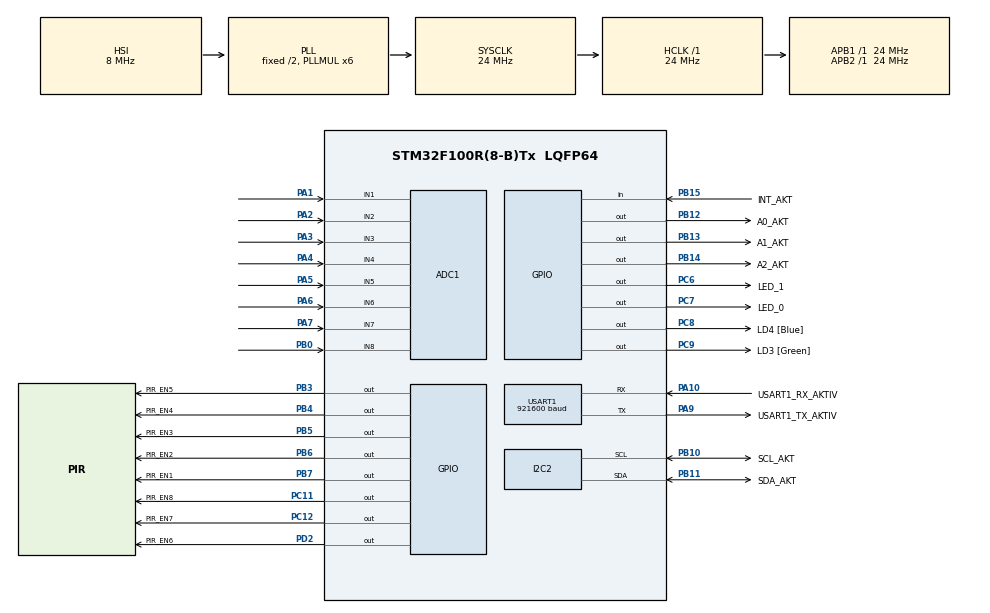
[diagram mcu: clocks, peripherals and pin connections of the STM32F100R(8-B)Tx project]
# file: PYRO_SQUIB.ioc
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ADC1.Channel-0\#ChannelRegularConversion=ADC_CHANNEL_1
ADC1.Channel-1\#ChannelRegularConversion=ADC_CHANNEL_2
ADC1.Channel-2\#ChannelRegularConversion=ADC_CHANNEL_3
ADC1.Channel-3\#ChannelRegularConversion=ADC_CHANNEL_4
ADC1.Channel-4\#ChannelRegularConversion=ADC_CHANNEL_5
ADC1.Channel-5\#ChannelRegularConversion=ADC_CHANNEL_6
ADC1.Channel-6\#ChannelRegularConversion=ADC_CHANNEL_7
ADC1.Channel-7\#ChannelRegularConversion=ADC_CHANNEL_8
ADC1.ContinuousConvMode=ENABLE
ADC1.DataAlign=ADC_DATAALIGN_RIGHT
ADC1.DiscontinuousConvMode=DISABLE
ADC1.EnableAnalogWatchDog=false
ADC1.EnableRegularConversion=ENABLE
ADC1.ExternalTrigConv=ADC_SOFTWARE_START
ADC1.InjNumberOfConversion=0
ADC1.NbrOfConversion=8
ADC1.NbrOfConversionFlag=1
ADC1.Rank-0\#ChannelRegularConversion=1
ADC1.Rank-1\#ChannelRegularConversion=2
ADC1.Rank-2\#ChannelRegularConversion=3
ADC1.Rank-3\#ChannelRegularConversion=4
ADC1.Rank-4\#ChannelRegularConversion=5
ADC1.Rank-5\#ChannelRegularConversion=6
ADC1.Rank-6\#ChannelRegularConversion=7
ADC1.Rank-7\#ChannelRegularConversion=8
ADC1.SamplingTime-0\#ChannelRegularConversion=ADC_SAMPLETIME_55CYCLES_5
ADC1.SamplingTime-1\#ChannelRegularConversion=ADC_SAMPLETIME_55CYCLES_5
ADC1.SamplingTime-2\#ChannelRegularConversion=ADC_SAMPLETIME_55CYCLES_5
ADC1.SamplingTime-3\#ChannelRegularConversion=ADC_SAMPLETIME_55CYCLES_5
ADC1.SamplingTime-4\#ChannelRegularConversion=ADC_SAMPLETIME_55CYCLES_5
ADC1.SamplingTime-5\#ChannelRegularConversion=ADC_SAMPLETIME_55CYCLES_5
ADC1.SamplingTime-6\#ChannelRegularConversion=ADC_SAMPLETIME_55CYCLES_5
ADC1.SamplingTime-7\#ChannelRegularConversion=ADC_SAMPLETIME_55CYCLES_5
ADC1.ScanConvMode=ADC_SCAN_ENABLE
ADC1.master=1
Dma.ADC1.2.Direction=DMA_PERIPH_TO_MEMORY
Dma.ADC1.2.Instance=DMA1_Channel1
Dma.ADC1.2.MemDataAlignment=DMA_MDATAALIGN_HALFWORD
Dma.ADC1.2.MemInc=DMA_MINC_ENABLE
Dma.ADC1.2.Mode=DMA_CIRCULAR
Dma.ADC1.2.PeriphDataAlignment=DMA_PDATAALIGN_HALFWORD
Dma.ADC1.2.PeriphInc=DMA_PINC_DISABLE
Dma.ADC1.2.Priority=DMA_PRIORITY_MEDIUM
Dma.Request0=USART1_RX
Dma.Request1=USART1_TX
Dma.Request2=ADC1
Dma.USART1_RX.0.Direction=DMA_PERIPH_TO_MEMORY
Dma.USART1_RX.0.Instance=DMA1_Channel5
Dma.USART1_RX.0.MemDataAlignment=DMA_MDATAALIGN_BYTE
Dma.USART1_RX.0.MemInc=DMA_MINC_ENABLE
Dma.USART1_RX.0.Mode=DMA_NORMAL
Dma.USART1_RX.0.PeriphDataAlignment=DMA_PDATAALIGN_BYTE
Dma.USART1_RX.0.PeriphInc=DMA_PINC_DISABLE
Dma.USART1_RX.0.Priority=DMA_PRIORITY_HIGH
Dma.USART1_TX.1.Direction=DMA_MEMORY_TO_PERIPH
Dma.USART1_TX.1.Instance=DMA1_Channel4
Dma.USART1_TX.1.MemDataAlignment=DMA_MDATAALIGN_BYTE
Dma.USART1_TX.1.MemInc=DMA_MINC_ENABLE
Dma.USART1_TX.1.Mode=DMA_NORMAL
Dma.USART1_TX.1.PeriphDataAlignment=DMA_PDATAALIGN_BYTE
Dma.USART1_TX.1.PeriphInc=DMA_PINC_DISABLE
Dma.USART1_TX.1.Priority=DMA_PRIORITY_HIGH
FREERTOS.HEAP_NUMBER=1
FREERTOS.INCLUDE_uxTaskPriorityGet=0
FREERTOS.INCLUDE_vTaskDelete=0
FREERTOS.Tasks01=defaultTask,-3,256,StartDefaultTask,Default,NULL,Dynamic,NULL,NULL
FREERTOS.configTOTAL_HEAP_SIZE=4096
Mcu.Family=STM32F1
Mcu.Name=STM32F100R(8-B)Tx
Mcu.Package=LQFP64
NVIC.DMA1_Channel1_IRQn=true\:7\:0\:true\:false\:true\:true
NVIC.DMA1_Channel4_IRQn=true\:5\:0\:false\:false\:true\:true
NVIC.DMA1_Channel5_IRQn=true\:5\:0\:false\:false\:true\:true
NVIC.PriorityGroup=NVIC_PRIORITYGROUP_4
NVIC.TIM2_IRQn=true\:5\:0\:false\:false\:true\:true
NVIC.TIM4_IRQn=true\:5\:0\:false\:false\:true\:true
NVIC.USART1_IRQn=true\:6\:0\:true\:false\:true\:true
PA1.Signal=ADCx_IN1
PA10.GPIO_Label=USART1_RX_AKTIV 
PA10.Mode=Asynchronous
PA10.Signal=USART1_RX
PA13.GPIO_Label=TMS_SWDIO
PA13.Mode=Serial_Wire
PA13.Signal=SYS_JTMS-SWDIO
PA14.GPIO_Label=TCK_SWCLK
PA14.Mode=Serial_Wire
PA14.Signal=SYS_JTCK-SWCLK
PA2.Signal=ADCx_IN2
PA3.Signal=ADCx_IN3
PA4.Signal=ADCx_IN4
PA5.Signal=ADCx_IN5
PA6.Signal=ADCx_IN6
PA7.Signal=ADCx_IN7
PA9.GPIO_Label=USART1_TX_AKTIV 
PA9.Mode=Asynchronous
PA9.Signal=USART1_TX
PB0.Signal=ADCx_IN8
PB10.GPIO_Label=SCL_AKT
PB10.Mode=I2C
PB10.Signal=I2C2_SCL
PB11.GPIO_Label=SDA_AKT
PB11.Mode=I2C
PB11.Signal=I2C2_SDA
PB12.GPIO_Label=A0_AKT
PB12.Signal=GPIO_Output
PB13.GPIO_Label=A1_AKT
PB13.Signal=GPIO_Output
PB14.GPIO_Label=A2_AKT
PB14.Signal=GPIO_Output
PB15.GPIO_Label=INT_AKT
PB15.Signal=GPIO_Input
PB3.GPIO_Label=PIR_EN5
PB3.Signal=GPIO_Output
PB4.GPIO_Label=PIR_EN4
PB4.Signal=GPIO_Output
PB5.GPIO_Label=PIR_EN3
PB5.Signal=GPIO_Output
PB6.GPIO_Label=PIR_EN2
PB6.Signal=GPIO_Output
PB7.GPIO_Label=PIR_EN1
PB7.Signal=GPIO_Output
PC11.GPIO_Label=PIR_EN8
PC11.Signal=GPIO_Output
PC12.GPIO_Label=PIR_EN7
PC12.Signal=GPIO_Output
PC14-OSC32_IN.Signal=RCC_OSC32_IN
PC15-OSC32_OUT.Signal=RCC_OSC32_OUT
PC6.GPIO_Label=LED_1
PC6.Signal=GPIO_Output
PC7.GPIO_Label=LED_0
PC7.Signal=GPIO_Output
PC8.GPIO_Label=LD4 [Blue]
PC8.Signal=GPIO_Output
PC9.GPIO_Label=LD3 [Green]
PC9.Signal=GPIO_Output
PD2.GPIO_Label=PIR_EN6
PD2.Signal=GPIO_Output
ProjectManager.HeapSize=0x200
ProjectManager.StackSize=0x400
ProjectManager.TargetToolchain=MDK-ARM V5
RCC.AHBFreq_Value=24000000
RCC.APB1Freq_Value=24000000
RCC.APB1TimFreq_Value=24000000
RCC.APB2Freq_Value=24000000
RCC.APB2TimFreq_Value=24000000
RCC.HCLKFreq_Value=24000000
RCC.PLLMUL=RCC_PLL_MUL6
RCC.SYSCLKFreq_VALUE=24000000
RCC.SYSCLKSource=RCC_SYSCLKSOURCE_PLLCLK
SH.ADCx_IN1.0=ADC1_IN1,IN1
SH.ADCx_IN2.0=ADC1_IN2,IN2
SH.ADCx_IN3.0=ADC1_IN3,IN3
SH.ADCx_IN4.0=ADC1_IN4,IN4
SH.ADCx_IN5.0=ADC1_IN5,IN5
SH.ADCx_IN6.0=ADC1_IN6,IN6
SH.ADCx_IN7.0=ADC1_IN7,IN7
SH.ADCx_IN8.0=ADC1_IN8,IN8
TIM2.Period=10
TIM2.Prescaler=24000
TIM4.Period=1200
USART1.BaudRate=921600
USART1.VirtualMode=VM_ASYNC
VP_FREERTOS_VS_ENABLE.Mode=Enabled
VP_TIM2_VS_ClockSourceINT.Mode=Internal
VP_TIM2_VS_OPM.Mode=OPM_bit
VP_TIM4_VS_ClockSourceINT.Mode=Internal
board=PYRO_SQUIB

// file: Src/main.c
/**
  ******************************************************************************
  * File Name          : main.c
  * Description        : Main program body
  ******************************************************************************
  *
  * Copyright (c) 2017 STMicroelectronics International N.V.
  * All rights reserved.
  *
  * Redistribution and use in source and binary forms, with or without
  * modification, are permitted, provided that the following conditions are met:
  *
  * 1. Redistribution of source code must retain the above copyright notice,
  *    this list of conditions and the following disclaimer.
  * 2. Redistributions in binary form must reproduce the above copyright notice,
  *    this list of conditions and the following disclaimer in the documentation
  *    and/or other materials provided with the distribution.
  * 3. Neither the name of STMicroelectronics nor the names of other
  *    contributors to this software may be used to endorse or promote products
  *    derived from this software without specific written permission.
  * 4. This software, including modifications and/or derivative works of this
  *    software, must execute solely and exclusively on microcontroller or
  *    microprocessor devices manufactured by or for STMicroelectronics.
  * 5. Redistribution and use of this software other than as permitted under
  *    this license is void and will automatically terminate your rights under
  *    this license.
  *
  * THIS SOFTWARE IS PROVIDED BY STMICROELECTRONICS AND CONTRIBUTORS "AS IS"
  * AND ANY EXPRESS, IMPLIED OR STATUTORY WARRANTIES, INCLUDING, BUT NOT
  * LIMITED TO, THE IMPLIED WARRANTIES OF MERCHANTABILITY, FITNESS FOR A
  * PARTICULAR PURPOSE AND NON-INFRINGEMENT OF THIRD PARTY INTELLECTUAL PROPERTY
  * RIGHTS ARE DISCLAIMED TO THE FULLEST EXTENT PERMITTED BY LAW. IN NO EVENT
  * SHALL STMICROELECTRONICS OR CONTRIBUTORS BE LIABLE FOR ANY DIRECT, INDIRECT,
  * INCIDENTAL, SPECIAL, EXEMPLARY, OR CONSEQUENTIAL DAMAGES (INCLUDING, BUT NOT
  * LIMITED TO, PROCUREMENT OF SUBSTITUTE GOODS OR SERVICES; LOSS OF USE, DATA,
  * OR PROFITS; OR BUSINESS INTERRUPTION) HOWEVER CAUSED AND ON ANY THEORY OF
  * LIABILITY, WHETHER IN CONTRACT, STRICT LIABILITY, OR TORT (INCLUDING
  * NEGLIGENCE OR OTHERWISE) ARISING IN ANY WAY OUT OF THE USE OF THIS SOFTWARE,
  * EVEN IF ADVISED OF THE POSSIBILITY OF SUCH DAMAGE.
  *
  ******************************************************************************
  */
#include "main.h"
#include "stm32f1xx_hal.h"
#include "cmsis_os.h"

/* USER CODE BEGIN Includes */
#include "mbinit.h"
#include "adc.h"
#include "dig_pot.h"
#include "pyro_squib.h"
#include "cfg_info.h"
/* USER CODE END Includes */

ADC_HandleTypeDef hadc1;
DMA_HandleTypeDef hdma_adc1;

I2C_HandleTypeDef hi2c2;

TIM_HandleTypeDef htim2;
TIM_HandleTypeDef htim4;

UART_HandleTypeDef huart1;
DMA_HandleTypeDef hdma_usart1_rx;
DMA_HandleTypeDef hdma_usart1_tx;

osThreadId defaultTaskHandle;

/* USER CODE BEGIN PV */
/* Private variables ---------------------------------------------------------*/

/* USER CODE END PV */

void SystemClock_Config(void);
void Error_Handler(void);
static void MX_GPIO_Init(void);
static void MX_DMA_Init(void);
static void MX_ADC1_Init(void);
static void MX_USART1_UART_Init(void);
static void MX_TIM4_Init(void);
static void MX_I2C2_Init(void);
static void MX_TIM2_Init(void);
void StartDefaultTask(void const * argument);

int main(void)
{

  /* MCU Configuration----------------------------------------------------------*/

  /* Reset of all peripherals, Initializes the Flash interface and the Systick. */
	HAL_Init();

  /* Configure the system clock */
//  SystemClock_Config();

  /* Initialize all configured peripherals */
	MX_GPIO_Init();
	MX_DMA_Init();
	MX_ADC1_Init();
	MX_USART1_UART_Init();
	MX_TIM4_Init();
	MX_I2C2_Init();
	MX_TIM2_Init();

  /* USER CODE BEGIN 2 */

	SystemClock_Config();
	ConfigInfoRead ();
	HAL_NVIC_DisableIRQ(DMA1_Channel1_IRQn);

	DigPot_Init();
	ADC_Init();
	PyroSquib_Init();
	Modbus_Init();

  /* USER CODE END 2 */

  /* Create the thread(s) */
  /* definition and creation of defaultTask */
//  osThreadDef(defaultTask, StartDefaultTask, osPriorityIdle, 5, 256);
//  defaultTaskHandle = osThreadCreate(osThread(defaultTask), NULL);

  /* Start scheduler */
  osKernelStart();

  /* We should never get here as control is now taken by the scheduler */

  /* Infinite loop */
  while (1)
  {

  }

}

/** System Clock Configuration
*/
void SystemClock_Config(void)
{

  RCC_OscInitTypeDef RCC_OscInitStruct;
  RCC_ClkInitTypeDef RCC_ClkInitStruct;
  RCC_PeriphCLKInitTypeDef PeriphClkInit;

    /**Initializes the CPU, AHB and APB busses clocks
    */
  RCC_OscInitStruct.OscillatorType = RCC_OSCILLATORTYPE_HSI;
  RCC_OscInitStruct.HSIState = RCC_HSI_ON;
  RCC_OscInitStruct.HSICalibrationValue = 16;
  RCC_OscInitStruct.PLL.PLLState = RCC_PLL_ON;
  RCC_OscInitStruct.PLL.PLLSource = RCC_PLLSOURCE_HSI_DIV2;
  RCC_OscInitStruct.PLL.PLLMUL = RCC_PLL_MUL6;
  if (HAL_RCC_OscConfig(&RCC_OscInitStruct) != HAL_OK)
  {
    Error_Handler();
  }

    /**Initializes the CPU, AHB and APB busses clocks
    */
  RCC_ClkInitStruct.ClockType = RCC_CLOCKTYPE_HCLK|RCC_CLOCKTYPE_SYSCLK
                              |RCC_CLOCKTYPE_PCLK1|RCC_CLOCKTYPE_PCLK2;
  RCC_ClkInitStruct.SYSCLKSource = RCC_SYSCLKSOURCE_PLLCLK;
  RCC_ClkInitStruct.AHBCLKDivider = RCC_SYSCLK_DIV1;
  RCC_ClkInitStruct.APB1CLKDivider = RCC_HCLK_DIV1;
  RCC_ClkInitStruct.APB2CLKDivider = RCC_HCLK_DIV1;

  if (HAL_RCC_ClockConfig(&RCC_ClkInitStruct, FLASH_LATENCY_0) != HAL_OK)
  {
    Error_Handler();
  }

  PeriphClkInit.PeriphClockSelection = RCC_PERIPHCLK_ADC;
  PeriphClkInit.AdcClockSelection = RCC_ADCPCLK2_DIV2;
  if (HAL_RCCEx_PeriphCLKConfig(&PeriphClkInit) != HAL_OK)
  {
    Error_Handler();
  }

    /**Configure the Systick interrupt time
    */
  HAL_SYSTICK_Config(HAL_RCC_GetHCLKFreq()/1000);

    /**Configure the Systick
    */
  HAL_SYSTICK_CLKSourceConfig(SYSTICK_CLKSOURCE_HCLK);

  /* SysTick_IRQn interrupt configuration */
  HAL_NVIC_SetPriority(SysTick_IRQn, 15, 0);
}

/* ADC1 init function */
static void MX_ADC1_Init(void)
{

  ADC_ChannelConfTypeDef sConfig;

    /**Common config
    */
  hadc1.Instance = ADC1;
  hadc1.Init.ScanConvMode = ADC_SCAN_ENABLE;
  hadc1.Init.ContinuousConvMode = ENABLE;
  hadc1.Init.DiscontinuousConvMode = DISABLE;
  hadc1.Init.ExternalTrigConv = ADC_SOFTWARE_START;
  hadc1.Init.DataAlign = ADC_DATAALIGN_RIGHT;
  hadc1.Init.NbrOfConversion = 8;
  if (HAL_ADC_Init(&hadc1) != HAL_OK)
  {
    Error_Handler();
  }

    /**Configure Regular Channel
    */
  sConfig.Channel = ADC_CHANNEL_1;
  sConfig.Rank = 1;
  sConfig.SamplingTime = ADC_SAMPLETIME_13CYCLES_5;
  if (HAL_ADC_ConfigChannel(&hadc1, &sConfig) != HAL_OK)
  {
    Error_Handler();
  }

    /**Configure Regular Channel
    */
  sConfig.Channel = ADC_CHANNEL_2;
  sConfig.Rank = 2;
  if (HAL_ADC_ConfigChannel(&hadc1, &sConfig) != HAL_OK)
  {
    Error_Handler();
  }

    /**Configure Regular Channel
    */
  sConfig.Channel = ADC_CHANNEL_3;
  sConfig.Rank = 3;
  if (HAL_ADC_ConfigChannel(&hadc1, &sConfig) != HAL_OK)
  {
    Error_Handler();
  }

    /**Configure Regular Channel
    */
  sConfig.Channel = ADC_CHANNEL_4;
  sConfig.Rank = 4;
  if (HAL_ADC_ConfigChannel(&hadc1, &sConfig) != HAL_OK)
  {
    Error_Handler();
  }

    /**Configure Regular Channel
    */
  sConfig.Channel = ADC_CHANNEL_5;
  sConfig.Rank = 5;
  if (HAL_ADC_ConfigChannel(&hadc1, &sConfig) != HAL_OK)
  {
    Error_Handler();
  }

    /**Configure Regular Channel
    */
  sConfig.Channel = ADC_CHANNEL_6;
  sConfig.Rank = 6;
  if (HAL_ADC_ConfigChannel(&hadc1, &sConfig) != HAL_OK)
  {
    Error_Handler();
  }

    /**Configure Regular Channel
    */
  sConfig.Channel = ADC_CHANNEL_7;
  sConfig.Rank = 7;
  if (HAL_ADC_ConfigChannel(&hadc1, &sConfig) != HAL_OK)
  {
    Error_Handler();
  }

    /**Configure Regular Channel
    */
  sConfig.Channel = ADC_CHANNEL_8;
  sConfig.Rank = 8;
  if (HAL_ADC_ConfigChannel(&hadc1, &sConfig) != HAL_OK)
  {
    Error_Handler();
  }

}

/* I2C2 init function */
static void MX_I2C2_Init(void)
{

  hi2c2.Instance = I2C2;
  hi2c2.Init.ClockSpeed = 100000;
  hi2c2.Init.DutyCycle = I2C_DUTYCYCLE_2;
  hi2c2.Init.OwnAddress1 = 0;
  hi2c2.Init.AddressingMode = I2C_ADDRESSINGMODE_7BIT;
  hi2c2.Init.DualAddressMode = I2C_DUALADDRESS_DISABLE;
  hi2c2.Init.OwnAddress2 = 0;
  hi2c2.Init.GeneralCallMode = I2C_GENERALCALL_DISABLE;
  hi2c2.Init.NoStretchMode = I2C_NOSTRETCH_DISABLE;
  if (HAL_I2C_Init(&hi2c2) != HAL_OK)
  {
    Error_Handler();
  }

}

/* TIM2 init function */
static void MX_TIM2_Init(void)
{

  TIM_ClockConfigTypeDef sClockSourceConfig;
  TIM_MasterConfigTypeDef sMasterConfig;

  htim2.Instance = TIM2;
  htim2.Init.Prescaler = 2400;
  htim2.Init.CounterMode = TIM_COUNTERMODE_UP;
  htim2.Init.Period = 10;
  htim2.Init.ClockDivision = TIM_CLOCKDIVISION_DIV1;
  if (HAL_TIM_Base_Init(&htim2) != HAL_OK)
  {
    Error_Handler();
  }

  sClockSourceConfig.ClockSource = TIM_CLOCKSOURCE_INTERNAL;
  if (HAL_TIM_ConfigClockSource(&htim2, &sClockSourceConfig) != HAL_OK)
  {
    Error_Handler();
  }

  if (HAL_TIM_OnePulse_Init(&htim2, TIM_OPMODE_SINGLE) != HAL_OK)
  {
    Error_Handler();
  }

  sMasterConfig.MasterOutputTrigger = TIM_TRGO_RESET;
  sMasterConfig.MasterSlaveMode = TIM_MASTERSLAVEMODE_DISABLE;
  if (HAL_TIMEx_MasterConfigSynchronization(&htim2, &sMasterConfig) != HAL_OK)
  {
    Error_Handler();
  }

}

/* TIM4 init function */
static void MX_TIM4_Init(void)
{

  TIM_ClockConfigTypeDef sClockSourceConfig;
  TIM_MasterConfigTypeDef sMasterConfig;

  htim4.Instance = TIM4;
  htim4.Init.Prescaler = 0;
  htim4.Init.CounterMode = TIM_COUNTERMODE_UP;
  htim4.Init.Period = 100;
  htim4.Init.ClockDivision = TIM_CLOCKDIVISION_DIV1;
  if (HAL_TIM_Base_Init(&htim4) != HAL_OK)
  {
    Error_Handler();
  }

  sClockSourceConfig.ClockSource = TIM_CLOCKSOURCE_INTERNAL;
  if (HAL_TIM_ConfigClockSource(&htim4, &sClockSourceConfig) != HAL_OK)
  {
    Error_Handler();
  }

  sMasterConfig.MasterOutputTrigger = TIM_TRGO_RESET;
  sMasterConfig.MasterSlaveMode = TIM_MASTERSLAVEMODE_DISABLE;
  if (HAL_TIMEx_MasterConfigSynchronization(&htim4, &sMasterConfig) != HAL_OK)
  {
    Error_Handler();
  }

}

/* USART1 init function */
static void MX_USART1_UART_Init(void)
{

  huart1.Instance = USART1;
  huart1.Init.BaudRate = 921600;
  huart1.Init.WordLength = UART_WORDLENGTH_8B;
  huart1.Init.StopBits = UART_STOPBITS_1;
  huart1.Init.Parity = UART_PARITY_NONE;
  huart1.Init.Mode = UART_MODE_TX_RX;
  huart1.Init.HwFlowCtl = UART_HWCONTROL_NONE;
  huart1.Init.OverSampling = UART_OVERSAMPLING_16;
  if (HAL_UART_Init(&huart1) != HAL_OK)
  {
    Error_Handler();
  }

}

static void MX_DMA_Init(void)
{
  /* DMA controller clock enable */
  __HAL_RCC_DMA1_CLK_ENABLE();

  /* DMA interrupt init */
  /* DMA1_Channel1_IRQn interrupt configuration */
  HAL_NVIC_SetPriority(DMA1_Channel1_IRQn, 7, 0);
  HAL_NVIC_EnableIRQ(DMA1_Channel1_IRQn);
  /* DMA1_Channel4_IRQn interrupt configuration */
  HAL_NVIC_SetPriority(DMA1_Channel4_IRQn, 5, 0);
  HAL_NVIC_EnableIRQ(DMA1_Channel4_IRQn);
  /* DMA1_Channel5_IRQn interrupt configuration */
  HAL_NVIC_SetPriority(DMA1_Channel5_IRQn, 5, 0);
  HAL_NVIC_EnableIRQ(DMA1_Channel5_IRQn);

}

/** Configure pins as
        * Analog
        * Input
        * Output
        * EVENT_OUT
        * EXTI
*/
static void MX_GPIO_Init(void)
{

  GPIO_InitTypeDef GPIO_InitStruct;

  /* GPIO Ports Clock Enable */
  __HAL_RCC_GPIOC_CLK_ENABLE();
  __HAL_RCC_GPIOA_CLK_ENABLE();
  __HAL_RCC_GPIOB_CLK_ENABLE();
  __HAL_RCC_GPIOD_CLK_ENABLE();

  /*Configure GPIO pin Output Level */
  HAL_GPIO_WritePin(GPIOB, A0_AKT_Pin|A1_AKT_Pin|A2_AKT_Pin|PIR_EN5_Pin
                          |PIR_EN4_Pin|PIR_EN3_Pin|PIR_EN2_Pin|PIR_EN1_Pin, GPIO_PIN_RESET);

  /*Configure GPIO pin Output Level */
  HAL_GPIO_WritePin(GPIOC, LED_1_Pin|LED_0_Pin|LD4_Pin|LD3_Pin
                          |PIR_EN8_Pin|PIR_EN7_Pin, GPIO_PIN_RESET);

  /*Configure GPIO pin Output Level */
  HAL_GPIO_WritePin(PIR_EN6_GPIO_Port, PIR_EN6_Pin, GPIO_PIN_RESET);

  /*Configure GPIO pins : A0_AKT_Pin A1_AKT_Pin A2_AKT_Pin PIR_EN5_Pin
                           PIR_EN4_Pin PIR_EN3_Pin PIR_EN2_Pin PIR_EN1_Pin */
  GPIO_InitStruct.Pin = A0_AKT_Pin|A1_AKT_Pin|A2_AKT_Pin|PIR_EN5_Pin
                          |PIR_EN4_Pin|PIR_EN3_Pin|PIR_EN2_Pin|PIR_EN1_Pin;
  GPIO_InitStruct.Mode = GPIO_MODE_OUTPUT_PP;
  GPIO_InitStruct.Speed = GPIO_SPEED_FREQ_LOW;
  HAL_GPIO_Init(GPIOB, &GPIO_InitStruct);

  /*Configure GPIO pin : INT_AKT_Pin */
  GPIO_InitStruct.Pin = INT_AKT_Pin;
  GPIO_InitStruct.Mode = GPIO_MODE_INPUT;
  GPIO_InitStruct.Pull = GPIO_NOPULL;
  HAL_GPIO_Init(INT_AKT_GPIO_Port, &GPIO_InitStruct);

  /*Configure GPIO pins : LED_1_Pin LED_0_Pin LD4_Pin LD3_Pin
                           PIR_EN8_Pin PIR_EN7_Pin */
  GPIO_InitStruct.Pin = LED_1_Pin|LED_0_Pin|LD4_Pin|LD3_Pin
                          |PIR_EN8_Pin|PIR_EN7_Pin;
  GPIO_InitStruct.Mode = GPIO_MODE_OUTPUT_PP;
  GPIO_InitStruct.Speed = GPIO_SPEED_FREQ_LOW;
  HAL_GPIO_Init(GPIOC, &GPIO_InitStruct);

  /*Configure GPIO pin : PIR_EN6_Pin */
  GPIO_InitStruct.Pin = PIR_EN6_Pin;
  GPIO_InitStruct.Mode = GPIO_MODE_OUTPUT_PP;
  GPIO_InitStruct.Speed = GPIO_SPEED_FREQ_LOW;
  HAL_GPIO_Init(PIR_EN6_GPIO_Port, &GPIO_InitStruct);

}

/* StartDefaultTask function */
void StartDefaultTask(void const * argument)
{

  /* USER CODE BEGIN 5 */
  /* Infinite loop */
	vTaskDelete(NULL);
  /* USER CODE END 5 */
}

void Error_Handler(void)
{
  while(1)
  {
  }
}

/************************ (C) COPYRIGHT STMicroelectronics *****END OF FILE****/
